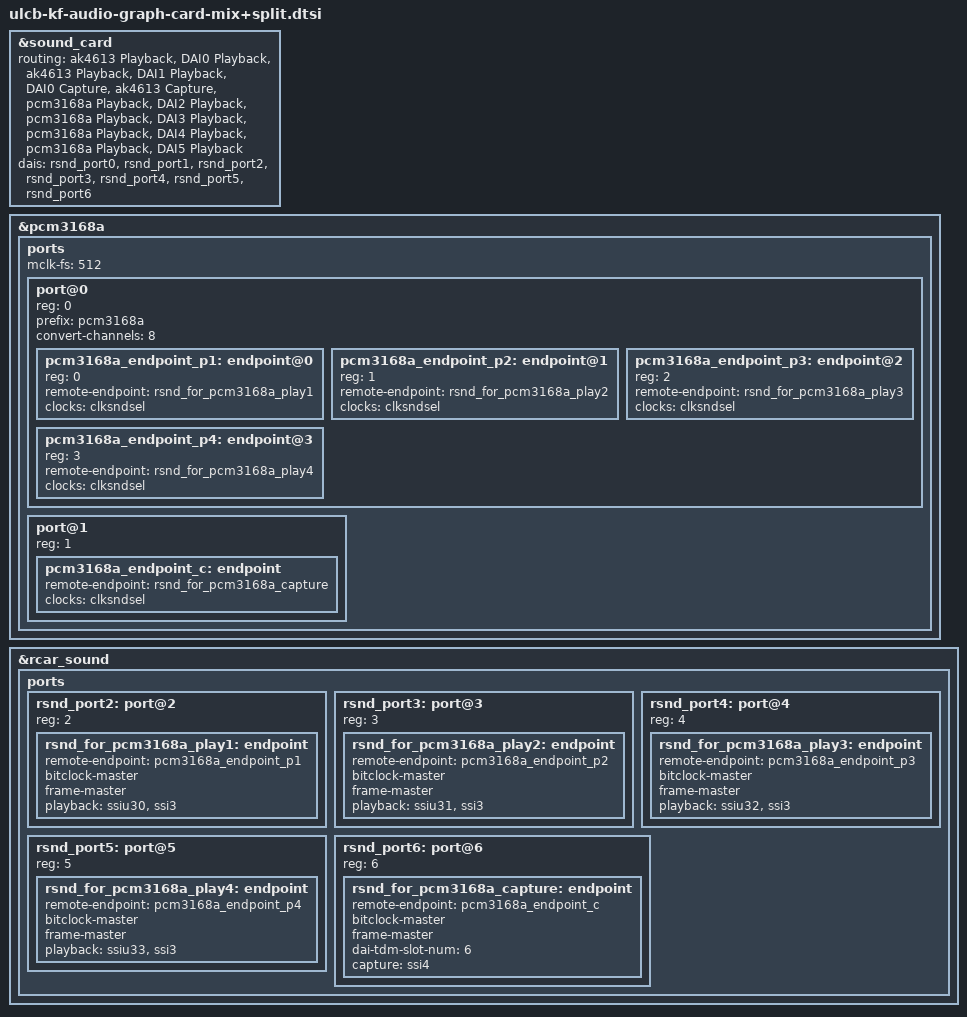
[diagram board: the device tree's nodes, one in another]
&sound_card {
	routing = "ak4613 Playback",   "DAI0 Playback",
		  "ak4613 Playback",   "DAI1 Playback",
		  "DAI0 Capture",      "ak4613 Capture",
		  "pcm3168a Playback", "DAI2 Playback",
		  "pcm3168a Playback", "DAI3 Playback",
		  "pcm3168a Playback", "DAI4 Playback",
		  "pcm3168a Playback", "DAI5 Playback";
	dais = <&rsnd_port0  
		&rsnd_port1  
		&rsnd_port2  
		&rsnd_port3  
		&rsnd_port4  
		&rsnd_port5  
		&rsnd_port6  
	>;
};
&pcm3168a {
	ports {
		#address-cells = <1>;
		#size-cells = <0>;
		mclk-fs = <512>;
		port@0 {
			#address-cells = <1>;
			#size-cells = <0>;
			reg = <0>;
			prefix = "pcm3168a";
			convert-channels = <8>;  
			pcm3168a_endpoint_p1: endpoint@0 {
				reg = <0>;
				remote-endpoint = <&rsnd_for_pcm3168a_play1>;
				clocks = <&clksndsel>;
			};
			pcm3168a_endpoint_p2: endpoint@1 {
				reg = <1>;
				remote-endpoint = <&rsnd_for_pcm3168a_play2>;
				clocks = <&clksndsel>;
			};
			pcm3168a_endpoint_p3: endpoint@2 {
				reg = <2>;
				remote-endpoint = <&rsnd_for_pcm3168a_play3>;
				clocks = <&clksndsel>;
			};
			pcm3168a_endpoint_p4: endpoint@3 {
				reg = <3>;
				remote-endpoint = <&rsnd_for_pcm3168a_play4>;
				clocks = <&clksndsel>;
			};
		};
		port@1 {
			reg = <1>;
			pcm3168a_endpoint_c: endpoint {
				remote-endpoint = <&rsnd_for_pcm3168a_capture>;
				clocks = <&clksndsel>;
			};
		};
	};
};
&rcar_sound {
	ports {
		rsnd_port2: port@2 {
			reg = <2>;
			rsnd_for_pcm3168a_play1: endpoint {
				remote-endpoint = <&pcm3168a_endpoint_p1>;
				bitclock-master;
				frame-master;
				playback = <&ssiu30 &ssi3>;
			};
		};
		rsnd_port3: port@3 {
			reg = <3>;
			rsnd_for_pcm3168a_play2: endpoint {
				remote-endpoint = <&pcm3168a_endpoint_p2>;
				bitclock-master;
				frame-master;
				playback = <&ssiu31 &ssi3>;
			};
		};
		rsnd_port4: port@4 {
			reg = <4>;
			rsnd_for_pcm3168a_play3: endpoint {
				remote-endpoint = <&pcm3168a_endpoint_p3>;
				bitclock-master;
				frame-master;
				playback = <&ssiu32 &ssi3>;
			};
		};
		rsnd_port5: port@5 {
			reg = <5>;
			rsnd_for_pcm3168a_play4: endpoint {
				remote-endpoint = <&pcm3168a_endpoint_p4>;
				bitclock-master;
				frame-master;
				playback = <&ssiu33 &ssi3>;
			};
		};
		rsnd_port6: port@6 {
			reg = <6>;
			rsnd_for_pcm3168a_capture: endpoint {
				remote-endpoint = <&pcm3168a_endpoint_c>;
				bitclock-master;
				frame-master;
				dai-tdm-slot-num = <6>;
				capture  = <&ssi4>;
			};
		};
	};
};
